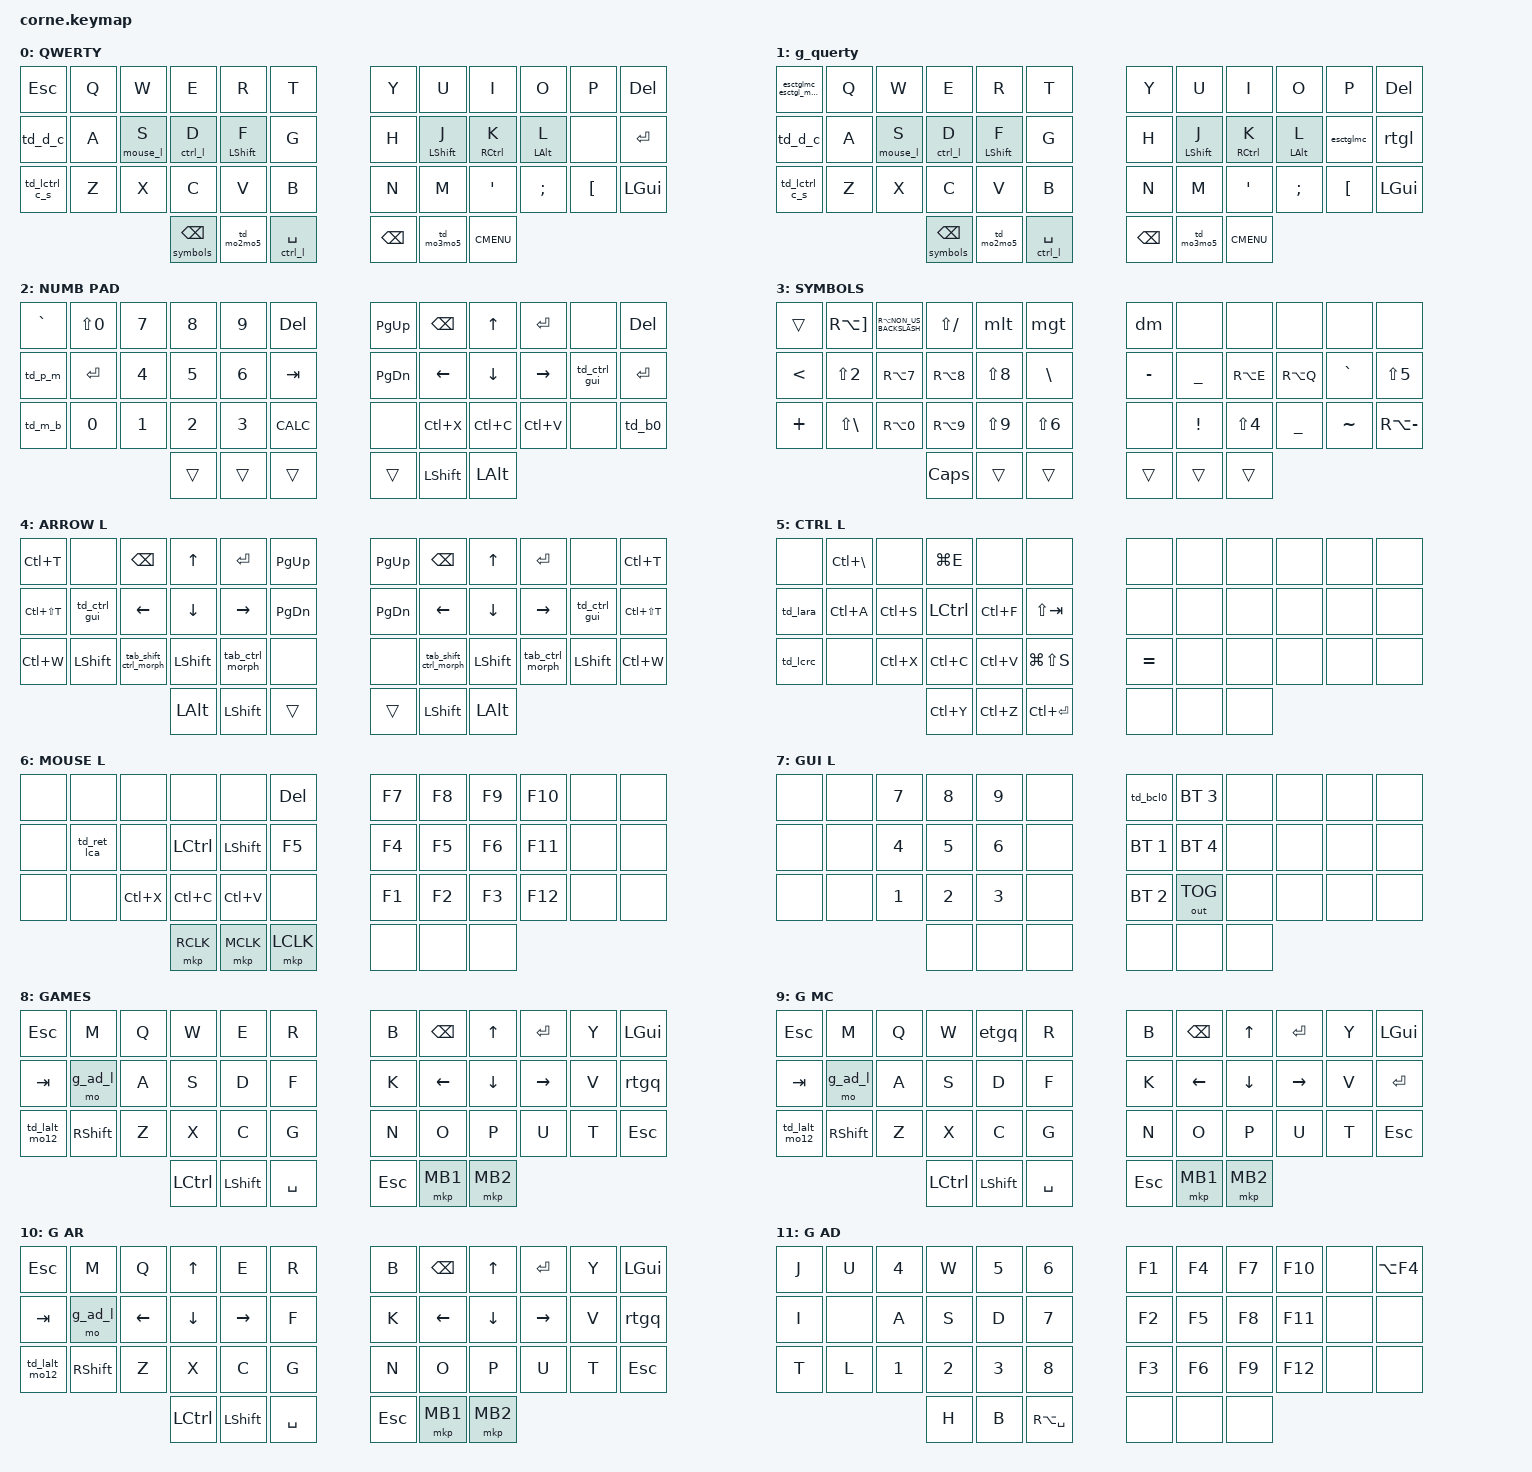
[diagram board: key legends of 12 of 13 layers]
/*
 * Copyright (c) 2020 The ZMK Contributors
 *
 * SPDX-License-Identifier: MIT
 */
// librarys 
#include <dt-bindings/zmk/behaviors.h>
#include <dt-bindings/zmk/mouse.h>
#include <dt-bindings/zmk/outputs.h>
#include <dt-bindings/zmk/bt.h>

// Self made
#include "combos.dtsi"
#include "macro.dtsi"
#include "behaviors.dtsi"
#include "layernames.dtsi"


&lt {
    tapping-term-ms = <150>;
};

&mt {
    flavor = "tap-preferred";
};

/ {
    keymap {
        compatible = "zmk,keymap";

        // in der layer wäre es noch gei lwenn man ein feature einbaut mit dem man das numb pad layer permanent da haben kann, also zb wenn man alt drückt und dei 37? dann soll die numb layer immer da sein (mod_morph oder so)
        qwerty {
            display-name = "QWERTY";
            bindings = <
                &kp ESC         &kp Q      &kp W           &kp E                &kp R           &kp T               &kp Y        &kp U             &kp I               &kp O           &kp P     &kp DEL
                &td_d_c         &kp A      &lt mouse_l S   &lt ctrl_l D         &mt LSHFT F     &kp G               &kp H        &mt LSHFT J       &mt RCTRL K         &mt LALT L      &none     &kp RET
                &td_lctrl_c_s   &kp Z      &kp X           &kp C                &kp V           &kp B               &kp N        &kp M             &kp SQT             &kp SEMI        &kp LBKT  &kp LGUI
                                                           &lt symbols BSPC     &td_mo2mo5      &lt ctrl_l SPACE    &kp BSPC     &td_mo3mo5        &kp K_CMENU
            >;
        };

        g_querty {
            display-name = "g_querty";
            bindings = <
                &esctglmc_esctgl_morph  &kp Q      &kp W           &kp E                &kp R           &kp T               &kp Y        &kp U             &kp I               &kp O           &kp P       &kp DEL
                &td_d_c                 &kp A      &lt mouse_l S   &lt ctrl_l D         &mt LSHFT F     &kp G               &kp H        &mt LSHFT J       &mt RCTRL K         &mt LALT L      &esctglmc   &rtgl
                &td_lctrl_c_s           &kp Z      &kp X           &kp C                &kp V           &kp B               &kp N        &kp M             &kp SQT             &kp SEMI        &kp LBKT    &kp LGUI
                                                                   &lt symbols BSPC     &td_mo2mo5      &lt ctrl_l SPACE    &kp BSPC     &td_mo3mo5        &kp K_CMENU
            >;
        };

        // und hier könnte man dann eigentlich noch ein mod morph einbauen die aus der homerow plus, minus, mal, durch machen kann
        numb_pad {
            display-name = "NUMB PAD";
            bindings = <
                &kp GRAVE       &kp LS(N0)  &kp N7  &kp N8   &kp N9   &kp DEL       &kp PAGE_UP       &kp BSPC      &kp UP         &kp RET       &none                 &kp DEL
                &td_p_m         &kp RET     &kp N4  &kp N5   &kp N6   &kp TAB       &kp PAGE_DOWN     &kp LEFT      &kp DOWN       &kp RIGHT     &td_ctrl_gui          &kp RET
                &td_m_b         &kp N0      &kp N1  &kp N2   &kp N3   &kp K_CALC    &none             &kp LC(X)     &kp LC(C)      &kp LC(V)     &none                 &td_b0
                                                    &trans   &trans   &trans        &trans            &kp LSHFT     &kp LALT
            >;
        };

        symbols {
            display-name = "SYMBOLS";
            bindings = <
                &trans         &kp RA(RBKT)         &kp RA(NON_US_BACKSLASH)   &kp LS(SLASH)      &mlt        &mgt          &dm             &none       &none            &none           &none         &none
                &kp LESS_THAN  &kp LS(N2)           &kp RA(N7)                 &kp RA(N8)         &kp LS(N8)  &kp BSLH      &kp MINUS       &kp UNDER   &kp RA(E)        &kp RA(Q)       &kp GRAVE     &kp LS(N5)
                &kp PLUS       &kp LS(BSLH)         &kp RA(N0)                 &kp RA(N9)         &kp LS(N9)  &kp LS(N6)    &none           &kp EXCL    &kp LS(N4)       &kp UNDER       &kp TILDE     &kp RA(MINUS)
                                                                               &kp CAPSLOCK       &trans      &trans        &trans          &trans      &trans
            >;
        };

        arr_layer {
            display-name = "ARROW L";
            bindings = <
                &kp LC(T)      &none            &kp BSPC                 &kp UP      &kp RET            &kp PAGE_UP       &kp PAGE_UP     &kp BSPC                  &kp UP      &kp RET             &none             &kp LC(T)
                &kp LC(LS(T))  &td_ctrl_gui     &kp LEFT                 &kp DOWN    &kp RIGHT          &kp PAGE_DOWN     &kp PAGE_DOWN   &kp LEFT                  &kp DOWN    &kp RIGHT           &td_ctrl_gui      &kp LC(LS(T))
                &kp LC(W)      &kp LSHFT        &tab_shift_ctrl_morph    &kp LSHFT   &tab_ctrl_morph    &none             &none           &tab_shift_ctrl_morph     &kp LSHFT   &tab_ctrl_morph     &kp LSHFT         &kp LC(W)
                                                                         &kp LALT    &kp LSHFT          &trans            &trans          &kp LSHFT                 &kp LALT
            >;
        };

        ctrl_l {
            display-name = "CTRL L";
            bindings = <
                &none         &kp LC(BSLH)  &none      &kp LG(E)  &none      &none            &none          &none          &none  &none  &none  &none
                &td_lara      &kp LC(A)     &kp LC(S)  &kp LCTRL  &kp LC(F)  &kp LS(TAB)      &none          &none          &none  &none  &none  &none 
                &td_lcrc      &none         &kp LC(X)  &kp LC(C)  &kp LC(V)  &kp LG(LS(S))    &kp EQUAL      &none          &none  &none  &none  &none
                                                       &kp LC(Y)  &kp LC(Z)  &kp LC(RET)      &none          &none          &none
            >;
        }; 

        mouse_l {
            display-name = "MOUSE L";
            bindings = <
                &none  &none        &none      &none       &none      &kp DEL      &kp F7  &kp F8   &kp F9     &kp F10    &none  &none  
                &none  &td_ret_lca  &none      &kp LCTRL   &kp LSHFT  &kp F5       &kp F4  &kp F5   &kp F6     &kp F11    &none  &none 
                &none  &none        &kp LC(X)  &kp LC(C)   &kp LC(V)  &none        &kp F1  &kp F2   &kp F3     &kp F12    &none  &none  
                                               &mkp RCLK   &mkp MCLK  &mkp LCLK    &none   &none    &none
            >;
        };

        gui_l {
            display-name = "GUI L";
            bindings = <
                &none  &none  &kp N7  &kp N8  &kp N9  &none    &td_bcl0      &bt BT_SEL 3  &none  &none  &none  &none
                &none  &none  &kp N4  &kp N5  &kp N6  &none    &bt BT_SEL 1  &bt BT_SEL 4  &none  &none  &none  &none
                &none  &none  &kp N1  &kp N2  &kp N3  &none    &bt BT_SEL 2  &out OUT_TOG  &none  &none  &none  &none
                                      &none   &none   &none    &none  &none  &none
            >;
        };

        g_l {
            display-name = "GAMES";
            bindings = < //
                &kp ESC           &kp M          &kp Q  &kp W      &kp E        &kp R        &kp B    &kp BSPC  &kp UP    &kp RET    &kp Y      &kp LGUI
                &kp TAB           &mo g_ad_l     &kp A  &kp S      &kp D        &kp F        &kp K    &kp LEFT  &kp DOWN  &kp RIGHT  &kp V      &rtgq
                &td_lalt_mo12     &kp RSHFT      &kp Z  &kp X      &kp C        &kp G        &kp N    &kp O     &kp P     &kp U      &kp T      &kp ESC
                                                        &kp LCTRL  &kp LSHFT    &kp SPACE    &kp ESC  &mkp MB1  &mkp MB2
            >;
        };

        g_l_mc {
            display-name = "G MC";
            bindings = < //
                &kp ESC           &kp M          &kp Q  &kp W      &etgq        &kp R        &kp B    &kp BSPC  &kp UP    &kp RET    &kp Y      &kp LGUI
                &kp TAB           &mo g_ad_l     &kp A  &kp S      &kp D        &kp F        &kp K    &kp LEFT  &kp DOWN  &kp RIGHT  &kp V      &kp RET
                &td_lalt_mo12     &kp RSHFT      &kp Z  &kp X      &kp C        &kp G        &kp N    &kp O     &kp P     &kp U      &kp T      &kp ESC
                                                        &kp LCTRL  &kp LSHFT    &kp SPACE    &kp ESC  &mkp MB1  &mkp MB2
            >;
        };


        g_ar_l  {
            display-name = "G AR";
            bindings = <
                &kp ESC             &kp M          &kp Q     &kp UP    &kp E        &kp R        &kp B    &kp BSPC  &kp UP    &kp RET    &kp Y      &kp LGUI
                &kp TAB             &mo g_ad_l     &kp LEFT  &kp DOWN  &kp RIGHT    &kp F        &kp K    &kp LEFT  &kp DOWN  &kp RIGHT  &kp V      &rtgq
                &td_lalt_mo12       &kp RSHFT      &kp Z     &kp X     &kp C        &kp G        &kp N    &kp O     &kp P     &kp U      &kp T      &kp ESC
                                                             &kp LCTRL &kp LSHFT    &kp SPACE    &kp ESC  &mkp MB1  &mkp MB2
            >;
        };

        g_ad_l {
            display-name = "G AD";
            bindings = <
                &kp J  &kp U  &kp N4  &kp W   &kp N5    &kp N6        &kp F1  &kp F4  &kp F7  &kp F10   &none   &kp LA(F4)
                &kp I  &none  &kp A   &kp S   &kp D     &kp N7        &kp F2  &kp F5  &kp F8  &kp F11   &none   &none                         
                &kp T  &kp L  &kp N1  &kp N2  &kp N3    &kp N8        &kp F3  &kp F6  &kp F9  &kp F12   &none   &none
                                      &kp H   &kp B     &kp RA(SPACE) &none   &none   &none
            >;
        };

        g_c_l {
            display-name = "G CTRL";
            bindings = <
                &none  &none  &none      &none      &none      &none    &none  &none  &none  &none  &none  &none
                &none  &none  &none      &kp LC(S)  &none      &none    &none  &none  &none  &none  &none  &none
                &none  &none  &kp LC(X)  &kp LC(C)  &kp LC(V)  &none    &none  &none  &none  &none  &none  &none
                                         &kp LC(Y)  &kp LC(Z)  &none    &none  &none  &none
            >;
        };
    };
};
